# WE2_S register map
Vendor: ARM Ltd.; Series: ARMv8.1-M Mainline; File version: 1.0
CPU: CM55 r1p1, little endian, MPU, FPU, double-precision FPU, DSP, VTOR, 3 interrupt priority bits
Registers are 32-bit, read-write, reset 0x0 unless marked. A register's access mark holds for its fields unless they carry their own. Offsets are from the block's base; [hi:lo] are bit positions.

## SCU_LSC
Base 0x52001000
0x100 SCU_SEN_CSW01_PCLK_D01_PINMUX
0x104 SCU_SEN_D27_FLVALID_PINMUX
0x108 SCU_SDIO_PINMUX
0x10C SCU_SSPIS_SW_PINMUX
0x110 SCU_SSPIM_PINMUX
0x114 SCU_GPIO012_PINMUX
0x118 SCU_UART0_PINMUX
0x11C SCU_PDM_PINMUX
0x120 SCU_SWDIO_OSPI_I2CM_UART2
0x130 SCU_I2CSLV_I3CSLV_SHARE_EN
0x300 SCU_CM55S_RESET_MASK
0x400 SCU_I2S_MODE
0x404 SCU_PDM_IP
0x408 SCU_REG_VMUTE_CTRL
0x40C SCU_REG_OSPI_RXDS_CTRL
0x410 SCU_REG_SEN_MCLK_CTRL_SRC_SEL
0x500 SCU_REG_AIP_DBG_MUX
0x818 SCU_DMA2_M1_AHBMSC_IDAUCFG
0x81C SCU_DMA2_M2_AHBMSC_IDAUCFG
0x820 SCU_DMA3_M1_AHBMSC_IDAUCFG
0x824 SCU_DMA3_M2_AHBMSC_IDAUCFG
0x850 SCU_AHB3_PPC_CFG_APNS
0x854 SCU_AHB3_PPC_CFG_INT
0x860 SCU_APB0NS_PPC_CFG_APNS
0x864 SCU_APB0NS_PPC_CFG_INT
0x868 SCU_APB0PS_PPC_CFG_APNS
0x86C SCU_APB0PS_PPC_CFG_INT
0x8A4 SCU_SRAM2_MPC_CFG_APNSINT
0xB0C SCU_VAD_D_PCM_DATA_SEL

## SENCTRL
Base 0x55005000
0x00 SENCTRL_MODE
0x04 SENCTRL_T_PRE_POST
0x08 SENCTRL_NFRAME
0x0C SENCTRL_FVLD_WDT
0x10 SENCTRL_TRIG_LOW_LINELENGTH
0x14 SENCTRL_STATE

## SENCTRL_LSC
Base 0x5200E000
0x00 SENCTRL_MODE
0x04 SENCTRL_T_PRE_POST
0x08 SENCTRL_NFRAME
0x0C SENCTRL_FVLD_WDT
0x10 SENCTRL_TRIG_LOW_LINELENGTH
0x14 SENCTRL_STATE

## QSPI_M — QSPI_M (spi 0)
Base 0x3A000000
Same registers: OSPI_M 0x3C000000, SSPI_M 0x50800000, SSPI_S 0x50810000
0x00 CTRLR0 — SPI Control Register 0
0x04 CTRLR1 — SPI Control Register 1
0x08 SSIENR — SPI Microwire Control Register
0x0C MWCR — SPI Slave Enable Register
0x10 SER — SPI Baud Rate Select Register
0x14 BAUDR — SPI Baud Rate Select Register
0x18 TXFTLR — SPI Transmit FIFO Threshold Level Register
0x1C RXFTLR — SPI Receive FIFO Threshold Level Register
0x20 TXFLR — SPI Transmit FIFO Level Register
0x24 RXFLR — SPI Receive FIFO Level Register
0x28 SR — SPI Status Register
0x2C IMR — SPI Interrupt Mask Register
0x30 ISR — SPI Interrupt Status Register
0x34 RISR — SPI Raw Interrupt Status Register
0x38 TXOICR — SPI Receive FIFO Overflow Interrupt Clear Register
0x3C RXOICR — SPI Receive FIFO Underflow Interrupt Clear Register
0x40 RXUICR — SPI Multi-Master Interrupt Clear Register
0x44 MSTICR — SPI Multi-Master Interrupt Clear Register
0x48 ICR — SPI Interrupt Clear Register
0x4C DMACR — DMA Control Register
0x50 DMATDLR — DMA Transmit Data Level
0x54 DMARDLR — DMA Receive Data Level
0x58 IDR — SPI Identification Register
0x5C SSI_VER_ID reset 0x3332322A — SPI CoreKit ID Register (Value after Reset : 0x3332322A)
0x60 DATAREG — SPI DATA Register for both Read and Write
0xF0 RX_SAMPLE_DLY — RxD Sample Delay Register
0xF4 SPI_CTRLR0
0xF8 DDR_DRIVE_EDGE
0xFC XIP_MODE_BITS
0x100 XIP_INCR_INST
0x104 XIP_WRAP_INST
0x108 XIP_CTRL
0x10C XIP_SER
0x110 XRXOICR
0x114 XIP_CNT_TIME_OUT
0x140 XIP_WRITE_INCR_INST
0x144 XIP_WRITE_WRAP_INST
0x148 XIP_WRITE_CTRL

## SWREG_AON
Base 0x5610F000
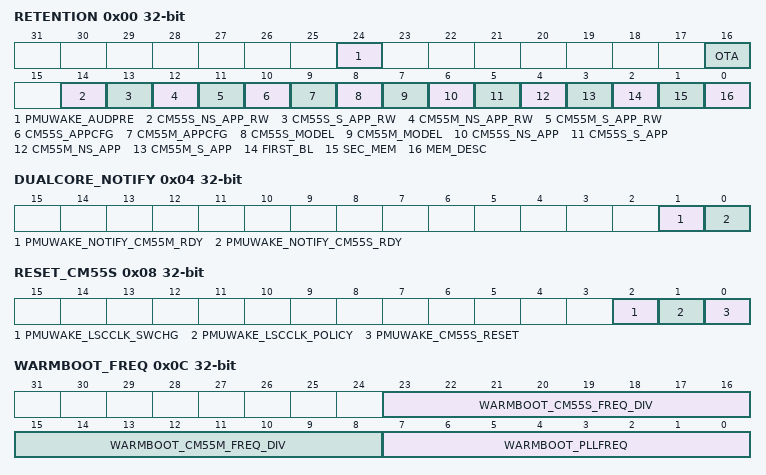
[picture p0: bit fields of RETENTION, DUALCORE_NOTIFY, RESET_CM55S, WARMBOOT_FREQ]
0x00 RETENTION
  [24] PMUWAKE_AUDPRE, [16] OTA, [14] CM55S_NS_APP_RW, [13] CM55S_S_APP_RW, [12] CM55M_NS_APP_RW, [11] CM55M_S_APP_RW, [10] CM55S_APPCFG, [9] CM55M_APPCFG, [8] CM55S_MODEL, [7] CM55M_MODEL, [6] CM55S_NS_APP, [5] CM55S_S_APP, [4] CM55M_NS_APP, [3] CM55M_S_APP, [2] FIRST_BL, [1] SEC_MEM, [0] MEM_DESC
0x04 DUALCORE_NOTIFY
  [1] PMUWAKE_NOTIFY_CM55M_RDY, [0] PMUWAKE_NOTIFY_CM55S_RDY
0x08 RESET_CM55S
  [2] PMUWAKE_LSCCLK_SWCHG, [1] PMUWAKE_LSCCLK_POLICY, [0] PMUWAKE_CM55S_RESET
0x0C WARMBOOT_FREQ
  [23:16] WARMBOOT_CM55S_FREQ_DIV, [15:8] WARMBOOT_CM55M_FREQ_DIV, [7:0] WARMBOOT_PLLFREQ
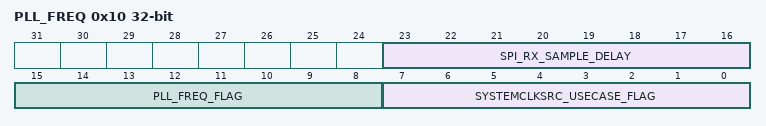
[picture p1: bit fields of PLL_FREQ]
0x10 PLL_FREQ
  [23:16] SPI_RX_SAMPLE_DELAY, [15:8] PLL_FREQ_FLAG, [7:0] SYSTEMCLKSRC_USECASE_FLAG
0x14 SW_STATUS
0x18 PLLFREQ
